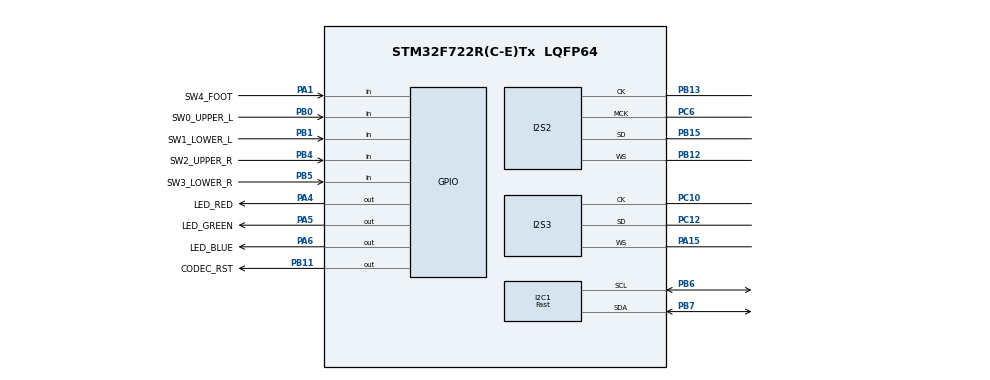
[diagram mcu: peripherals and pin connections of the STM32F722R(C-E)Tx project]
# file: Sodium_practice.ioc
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Mcu.Family=STM32F7
Dma.SPI2_TX.0.MemInc=DMA_MINC_ENABLE
PH0-OSC_IN.Signal=RCC_OSC_IN
RCC.CortexFreq_Value=216000000
I2C1.I2C_Speed_Mode=I2C_Fast
PC12.Signal=I2S3_SD
PC10.Signal=I2S3_CK
CORTEX_M7.PREFETCH_ENABLE=1
PA6.GPIO_Label=LED_BLUE
PB0.GPIO_Label=SW0_UPPER_L
PB11.Signal=GPIO_Output
NVIC.DMA1_Stream4_IRQn=true\:5\:0\:false\:false\:true\:true\:false\:true
PB13.Signal=I2S2_CK
PB15.Signal=I2S2_SD
Dma.SPI2_TX.0.Instance=DMA1_Stream4
RCC.SYSCLKSource=RCC_SYSCLKSOURCE_PLLCLK
ProjectManager.StackSize=0x4000
Dma.SPI2_TX.0.MemDataAlignment=DMA_MDATAALIGN_HALFWORD
FREERTOS.configENABLE_FPU=1
PB1.GPIO_PuPd=GPIO_PULLUP
RCC.HCLKFreq_Value=216000000
I2S3.Mode=I2S_MODE_SLAVE_RX
RCC.APB2TimFreq_Value=216000000
PB6.Signal=I2C1_SCL
PB6.Mode=I2C
Dma.SPI2_TX.0.Mode=DMA_CIRCULAR
PA1.GPIO_PuPd=GPIO_PULLUP
RCC.AHBFreq_Value=216000000
PH0-OSC_IN.Mode=HSE-External-Oscillator
RCC.HSE_VALUE=8000000
PA15.Mode=Half_Duplex_Slave
I2S3.ErrorAudioFreq=0.24 %
PA14.Mode=Serial_Wire
PB1.GPIO_Label=SW1_LOWER_L
PB7.Signal=I2C1_SDA
I2S2.DataFormat=I2S_DATAFORMAT_32B
VP_FREERTOS_VS_CMSIS_V1.Mode=CMSIS_V1
PH1-OSC_OUT.Mode=HSE-External-Oscillator
Mcu.Package=LQFP64
PB1.Signal=GPIO_Input
PA6.Signal=GPIO_Output
PB12.Mode=Half_Duplex_Master
NVIC.TimeBase=TIM7_IRQn
Dma.SPI3_RX.1.MemInc=DMA_MINC_ENABLE
NVIC.TimeBaseIP=TIM7
PA15.Signal=I2S3_WS
Dma.SPI2_TX.0.PeriphInc=DMA_PINC_DISABLE
RCC.APB2CLKDivider=RCC_HCLK_DIV2
PB5.GPIO_Label=SW3_LOWER_R
Dma.Request1=SPI3_RX
RCC.APB1TimFreq_Value=108000000
NVIC.DMA1_Stream0_IRQn=true\:5\:0\:false\:false\:true\:true\:false\:true
PB13.Mode=Half_Duplex_Master
Dma.Request0=SPI2_TX
PA4.GPIO_Label=LED_RED
NVIC.TIM7_IRQn=true\:0\:0\:false\:false\:true\:false\:false\:true
PB4.Signal=GPIO_Input
RCC.PLLSourceVirtual=RCC_PLLSOURCE_HSE
Dma.SPI3_RX.1.PeriphDataAlignment=DMA_PDATAALIGN_HALFWORD
I2S2.AudioFreq=I2S_AUDIOFREQ_44K
I2S3.FullDuplexMode=I2S_FULLDUPLEXMODE_DISABLE
CORTEX_M7.CPU_ICache=Enabled
FREERTOS.Tasks01=startTask,0,1024,StartDefaultTask,Default,NULL,Dynamic,NULL,NULL
I2S2.Instance=SPI$Index
VP_SYS_VS_tim7.Mode=TIM7
RCC.I2C1CLockSelection=RCC_I2C1CLKSOURCE_SYSCLK
PC10.Mode=Half_Duplex_Slave
PC6.Signal=I2S2_MCK
PB11.GPIO_Label=CODEC_RST
Dma.SPI3_RX.1.FIFOMode=DMA_FIFOMODE_DISABLE
Dma.SPI3_RX.1.PeriphInc=DMA_PINC_DISABLE
RCC.APB1CLKDivider=RCC_HCLK_DIV4
Dma.SPI3_RX.1.Priority=DMA_PRIORITY_VERY_HIGH
I2S3.DataFormat=I2S_DATAFORMAT_32B
Dma.SPI3_RX.1.Instance=DMA1_Stream0
Dma.SPI3_RX.1.MemDataAlignment=DMA_MDATAALIGN_HALFWORD
PA13.Signal=SYS_JTMS-SWDIO
ProjectManager.TargetToolchain=STM32CubeIDE
CORTEX_M7.ART_ACCLERATOR_ENABLE=1
PC6.Mode=Master_Clock_Activated
I2S2.VirtualMode=I2S_MODE_MASTER
I2C1.Timing=0x10A03AC5
I2S3.VirtualMode=I2S_MODE_SLAVE
PB4.GPIO_PuPd=GPIO_PULLUP
RCC.USBFreq_Value=216000000
RCC.LSE_VALUE=32768
PA1.Signal=GPIO_Input
PA5.Signal=GPIO_Output
I2S3.AudioFreq=I2S_AUDIOFREQ_44K
PC12.Mode=Half_Duplex_Slave
board=custom
RCC.VCOOutputFreq_Value=432000000
PB15.Mode=Half_Duplex_Master
RCC.APB2Freq_Value=108000000
PB4.GPIO_Label=SW2_UPPER_R
Dma.SPI2_TX.0.PeriphDataAlignment=DMA_PDATAALIGN_HALFWORD
PA1.GPIO_Label=SW4_FOOT
PH1-OSC_OUT.Signal=RCC_OSC_OUT
PA13.Mode=Serial_Wire
Mcu.Name=STM32F722R(C-E)Tx
Dma.SPI2_TX.0.FIFOMode=DMA_FIFOMODE_DISABLE
I2S2.FullDuplexMode=I2S_FULLDUPLEXMODE_DISABLE
PA4.Signal=GPIO_Output
Dma.SPI2_TX.0.Priority=DMA_PRIORITY_VERY_HIGH
RCC.SYSCLKFreq_VALUE=216000000
PB5.Signal=GPIO_Input
PA5.GPIO_Label=LED_GREEN
I2S2.ErrorAudioFreq=0.24 %
PB5.GPIO_PuPd=GPIO_PULLUP
PB7.Mode=I2C
Dma.SPI3_RX.1.Direction=DMA_PERIPH_TO_MEMORY
PA14.Signal=SYS_JTCK-SWCLK
ProjectManager.HeapSize=0x2000
Dma.SPI3_RX.1.Mode=DMA_CIRCULAR
RCC.HSI_VALUE=16000000
NVIC.PriorityGroup=NVIC_PRIORITYGROUP_4
I2S3.RealAudioFreq=44.108 KHz
RCC.PLLM=8
RCC.PLLN=432
CORTEX_M7.CPU_DCache=Enabled
I2S3.Instance=SPI$Index
Dma.SPI2_TX.0.Direction=DMA_MEMORY_TO_PERIPH
RCC.APB1Freq_Value=54000000
RCC.PLLI2SR=3
PB0.Signal=GPIO_Input
I2S2.RealAudioFreq=44.108 KHz
RCC.PLLI2SN=271
PB12.Signal=I2S2_WS
PB0.GPIO_PuPd=GPIO_PULLUP

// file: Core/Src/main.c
/* USER CODE BEGIN Header */
/**
 ******************************************************************************
 * @file           : main.c
 * @brief          : Main program body
 ******************************************************************************
 * @attention
 *
 * <h2><center>&copy; Copyright (c) 2021 STMicroelectronics.
 * All rights reserved.</center></h2>
 *
 * This software component is licensed by ST under Ultimate Liberty license
 * SLA0044, the "License"; You may not use this file except in compliance with
 * the License. You may obtain a copy of the License at:
 *                             www.st.com/SLA0044
 *
 ******************************************************************************
 */
/* USER CODE END Header */
#include "main.h"
#include "cmsis_os.h"

I2S_HandleTypeDef hi2s2;
I2S_HandleTypeDef hi2s3;
DMA_HandleTypeDef hdma_spi2_tx;
DMA_HandleTypeDef hdma_spi3_rx;

osThreadId startTaskHandle;

void SystemClock_Config(void);
static void MX_GPIO_Init(void);
static void MX_DMA_Init(void);
static void MX_I2C1_Init(void);
static void MX_I2S2_Init(void);
static void MX_I2S3_Init(void);
void StartDefaultTask(void const * argument);

int main(void)
{

  /* Enable I-Cache---------------------------------------------------------*/
  SCB_EnableICache();

  /* Enable D-Cache---------------------------------------------------------*/
  SCB_EnableDCache();

  /* MCU Configuration--------------------------------------------------------*/

  /* Reset of all peripherals, Initializes the Flash interface and the Systick. */
  HAL_Init();

  /* Configure the system clock */
  SystemClock_Config();

  /* Initialize all configured peripherals */
  MX_GPIO_Init();
  MX_DMA_Init();
  MX_I2C1_Init();
  MX_I2S2_Init();
  MX_I2S3_Init();

  /* Create the thread(s) */
  /* definition and creation of startTask */
  osThreadDef(startTask, StartDefaultTask, osPriorityNormal, 0, 1024);
  startTaskHandle = osThreadCreate(osThread(startTask), NULL);

  /* Start scheduler */
  osKernelStart();

  /* We should never get here as control is now taken by the scheduler */
  /* Infinite loop */
    while (1) {

    }
}

void SystemClock_Config(void)
{
  LL_FLASH_SetLatency(LL_FLASH_LATENCY_7);
  while(LL_FLASH_GetLatency()!= LL_FLASH_LATENCY_7)
  {
  }
  LL_PWR_SetRegulVoltageScaling(LL_PWR_REGU_VOLTAGE_SCALE1);
  LL_PWR_EnableOverDriveMode();
  LL_RCC_HSE_Enable();

   /* Wait till HSE is ready */
  while(LL_RCC_HSE_IsReady() != 1)
  {

  }
  LL_RCC_PLL_ConfigDomain_SYS(LL_RCC_PLLSOURCE_HSE, LL_RCC_PLLM_DIV_8, 432, LL_RCC_PLLP_DIV_2);
  LL_RCC_PLLI2S_ConfigDomain_I2S(LL_RCC_PLLSOURCE_HSE, LL_RCC_PLLM_DIV_8, 271, LL_RCC_PLLI2SR_DIV_3);
  LL_RCC_PLL_Enable();

   /* Wait till PLL is ready */
  while(LL_RCC_PLL_IsReady() != 1)
  {

  }
  LL_RCC_PLLI2S_Enable();

   /* Wait till PLL is ready */
  while(LL_RCC_PLLI2S_IsReady() != 1)
  {

  }
  LL_RCC_SetAHBPrescaler(LL_RCC_SYSCLK_DIV_1);
  LL_RCC_SetAPB1Prescaler(LL_RCC_APB1_DIV_4);
  LL_RCC_SetAPB2Prescaler(LL_RCC_APB2_DIV_2);
  LL_RCC_SetSysClkSource(LL_RCC_SYS_CLKSOURCE_PLL);

   /* Wait till System clock is ready */
  while(LL_RCC_GetSysClkSource() != LL_RCC_SYS_CLKSOURCE_STATUS_PLL)
  {

  }
  LL_SetSystemCoreClock(216000000);

   /* Update the time base */
  if (HAL_InitTick (TICK_INT_PRIORITY) != HAL_OK)
  {
    Error_Handler();
  }
  LL_RCC_SetI2SClockSource(LL_RCC_I2S1_CLKSOURCE_PLLI2S);
  LL_RCC_SetI2CClockSource(LL_RCC_I2C1_CLKSOURCE_SYSCLK);
}

static void MX_I2C1_Init(void)
{

  LL_I2C_InitTypeDef I2C_InitStruct = {0};

  LL_GPIO_InitTypeDef GPIO_InitStruct = {0};

  LL_AHB1_GRP1_EnableClock(LL_AHB1_GRP1_PERIPH_GPIOB);
  /**I2C1 GPIO Configuration
  PB6   ------> I2C1_SCL
  PB7   ------> I2C1_SDA
  */
  GPIO_InitStruct.Pin = LL_GPIO_PIN_6;
  GPIO_InitStruct.Mode = LL_GPIO_MODE_ALTERNATE;
  GPIO_InitStruct.Speed = LL_GPIO_SPEED_FREQ_VERY_HIGH;
  GPIO_InitStruct.OutputType = LL_GPIO_OUTPUT_OPENDRAIN;
  GPIO_InitStruct.Pull = LL_GPIO_PULL_UP;
  GPIO_InitStruct.Alternate = LL_GPIO_AF_4;
  LL_GPIO_Init(GPIOB, &GPIO_InitStruct);

  GPIO_InitStruct.Pin = LL_GPIO_PIN_7;
  GPIO_InitStruct.Mode = LL_GPIO_MODE_ALTERNATE;
  GPIO_InitStruct.Speed = LL_GPIO_SPEED_FREQ_VERY_HIGH;
  GPIO_InitStruct.OutputType = LL_GPIO_OUTPUT_OPENDRAIN;
  GPIO_InitStruct.Pull = LL_GPIO_PULL_UP;
  GPIO_InitStruct.Alternate = LL_GPIO_AF_4;
  LL_GPIO_Init(GPIOB, &GPIO_InitStruct);

  /* Peripheral clock enable */
  LL_APB1_GRP1_EnableClock(LL_APB1_GRP1_PERIPH_I2C1);

  /** I2C Initialization
  */
  LL_I2C_EnableAutoEndMode(I2C1);
  LL_I2C_SetOwnAddress2(I2C1, 0, LL_I2C_OWNADDRESS2_NOMASK);
  LL_I2C_DisableOwnAddress2(I2C1);
  LL_I2C_DisableGeneralCall(I2C1);
  LL_I2C_EnableClockStretching(I2C1);
  I2C_InitStruct.PeripheralMode = LL_I2C_MODE_I2C;
  I2C_InitStruct.Timing = 0x10A03AC5;
  I2C_InitStruct.AnalogFilter = LL_I2C_ANALOGFILTER_ENABLE;
  I2C_InitStruct.DigitalFilter = 0;
  I2C_InitStruct.OwnAddress1 = 0;
  I2C_InitStruct.TypeAcknowledge = LL_I2C_ACK;
  I2C_InitStruct.OwnAddrSize = LL_I2C_OWNADDRESS1_7BIT;
  LL_I2C_Init(I2C1, &I2C_InitStruct);

}

static void MX_I2S2_Init(void)
{

  hi2s2.Instance = SPI2;
  hi2s2.Init.Mode = I2S_MODE_MASTER_TX;
  hi2s2.Init.Standard = I2S_STANDARD_PHILIPS;
  hi2s2.Init.DataFormat = I2S_DATAFORMAT_32B;
  hi2s2.Init.MCLKOutput = I2S_MCLKOUTPUT_ENABLE;
  hi2s2.Init.AudioFreq = I2S_AUDIOFREQ_44K;
  hi2s2.Init.CPOL = I2S_CPOL_LOW;
  hi2s2.Init.ClockSource = I2S_CLOCK_PLL;
  if (HAL_I2S_Init(&hi2s2) != HAL_OK)
  {
    Error_Handler();
  }

}

static void MX_I2S3_Init(void)
{

  hi2s3.Instance = SPI3;
  hi2s3.Init.Mode = I2S_MODE_SLAVE_RX;
  hi2s3.Init.Standard = I2S_STANDARD_PHILIPS;
  hi2s3.Init.DataFormat = I2S_DATAFORMAT_32B;
  hi2s3.Init.MCLKOutput = I2S_MCLKOUTPUT_DISABLE;
  hi2s3.Init.AudioFreq = I2S_AUDIOFREQ_44K;
  hi2s3.Init.CPOL = I2S_CPOL_LOW;
  hi2s3.Init.ClockSource = I2S_CLOCK_PLL;
  if (HAL_I2S_Init(&hi2s3) != HAL_OK)
  {
    Error_Handler();
  }

}

static void MX_DMA_Init(void)
{

  /* Init with LL driver */
  /* DMA controller clock enable */
  LL_AHB1_GRP1_EnableClock(LL_AHB1_GRP1_PERIPH_DMA1);

  /* DMA interrupt init */
  /* DMA1_Stream0_IRQn interrupt configuration */
  HAL_NVIC_SetPriority(DMA1_Stream0_IRQn, 5, 0);
  HAL_NVIC_EnableIRQ(DMA1_Stream0_IRQn);
  /* DMA1_Stream4_IRQn interrupt configuration */
  HAL_NVIC_SetPriority(DMA1_Stream4_IRQn, 5, 0);
  HAL_NVIC_EnableIRQ(DMA1_Stream4_IRQn);

}

static void MX_GPIO_Init(void)
{
  LL_GPIO_InitTypeDef GPIO_InitStruct = {0};

  /* GPIO Ports Clock Enable */
  LL_AHB1_GRP1_EnableClock(LL_AHB1_GRP1_PERIPH_GPIOH);
  LL_AHB1_GRP1_EnableClock(LL_AHB1_GRP1_PERIPH_GPIOA);
  LL_AHB1_GRP1_EnableClock(LL_AHB1_GRP1_PERIPH_GPIOB);
  LL_AHB1_GRP1_EnableClock(LL_AHB1_GRP1_PERIPH_GPIOC);

  /**/
  LL_GPIO_ResetOutputPin(LED_RED_GPIO_Port, LED_RED_Pin);

  /**/
  LL_GPIO_ResetOutputPin(LED_GREEN_GPIO_Port, LED_GREEN_Pin);

  /**/
  LL_GPIO_ResetOutputPin(LED_BLUE_GPIO_Port, LED_BLUE_Pin);

  /**/
  LL_GPIO_ResetOutputPin(CODEC_RST_GPIO_Port, CODEC_RST_Pin);

  /**/
  GPIO_InitStruct.Pin = SW4_FOOT_Pin;
  GPIO_InitStruct.Mode = LL_GPIO_MODE_INPUT;
  GPIO_InitStruct.Pull = LL_GPIO_PULL_UP;
  LL_GPIO_Init(SW4_FOOT_GPIO_Port, &GPIO_InitStruct);

  /**/
  GPIO_InitStruct.Pin = LED_RED_Pin;
  GPIO_InitStruct.Mode = LL_GPIO_MODE_OUTPUT;
  GPIO_InitStruct.Speed = LL_GPIO_SPEED_FREQ_LOW;
  GPIO_InitStruct.OutputType = LL_GPIO_OUTPUT_PUSHPULL;
  GPIO_InitStruct.Pull = LL_GPIO_PULL_NO;
  LL_GPIO_Init(LED_RED_GPIO_Port, &GPIO_InitStruct);

  /**/
  GPIO_InitStruct.Pin = LED_GREEN_Pin;
  GPIO_InitStruct.Mode = LL_GPIO_MODE_OUTPUT;
  GPIO_InitStruct.Speed = LL_GPIO_SPEED_FREQ_LOW;
  GPIO_InitStruct.OutputType = LL_GPIO_OUTPUT_PUSHPULL;
  GPIO_InitStruct.Pull = LL_GPIO_PULL_NO;
  LL_GPIO_Init(LED_GREEN_GPIO_Port, &GPIO_InitStruct);

  /**/
  GPIO_InitStruct.Pin = LED_BLUE_Pin;
  GPIO_InitStruct.Mode = LL_GPIO_MODE_OUTPUT;
  GPIO_InitStruct.Speed = LL_GPIO_SPEED_FREQ_LOW;
  GPIO_InitStruct.OutputType = LL_GPIO_OUTPUT_PUSHPULL;
  GPIO_InitStruct.Pull = LL_GPIO_PULL_NO;
  LL_GPIO_Init(LED_BLUE_GPIO_Port, &GPIO_InitStruct);

  /**/
  GPIO_InitStruct.Pin = SW0_UPPER_L_Pin;
  GPIO_InitStruct.Mode = LL_GPIO_MODE_INPUT;
  GPIO_InitStruct.Pull = LL_GPIO_PULL_UP;
  LL_GPIO_Init(SW0_UPPER_L_GPIO_Port, &GPIO_InitStruct);

  /**/
  GPIO_InitStruct.Pin = SW1_LOWER_L_Pin;
  GPIO_InitStruct.Mode = LL_GPIO_MODE_INPUT;
  GPIO_InitStruct.Pull = LL_GPIO_PULL_UP;
  LL_GPIO_Init(SW1_LOWER_L_GPIO_Port, &GPIO_InitStruct);

  /**/
  GPIO_InitStruct.Pin = CODEC_RST_Pin;
  GPIO_InitStruct.Mode = LL_GPIO_MODE_OUTPUT;
  GPIO_InitStruct.Speed = LL_GPIO_SPEED_FREQ_LOW;
  GPIO_InitStruct.OutputType = LL_GPIO_OUTPUT_PUSHPULL;
  GPIO_InitStruct.Pull = LL_GPIO_PULL_NO;
  LL_GPIO_Init(CODEC_RST_GPIO_Port, &GPIO_InitStruct);

  /**/
  GPIO_InitStruct.Pin = SW2_UPPER_R_Pin;
  GPIO_InitStruct.Mode = LL_GPIO_MODE_INPUT;
  GPIO_InitStruct.Pull = LL_GPIO_PULL_UP;
  LL_GPIO_Init(SW2_UPPER_R_GPIO_Port, &GPIO_InitStruct);

  /**/
  GPIO_InitStruct.Pin = SW3_LOWER_R_Pin;
  GPIO_InitStruct.Mode = LL_GPIO_MODE_INPUT;
  GPIO_InitStruct.Pull = LL_GPIO_PULL_UP;
  LL_GPIO_Init(SW3_LOWER_R_GPIO_Port, &GPIO_InitStruct);

}

void StartDefaultTask(void const * argument)
{
  /* USER CODE BEGIN 5 */
    /* Infinite loop */
    for (;;) {
        osDelay(500);
        LL_GPIO_TogglePin(LED_RED_GPIO_Port, LED_RED_Pin);
        LL_GPIO_TogglePin(LED_GREEN_GPIO_Port, LED_GREEN_Pin);
        LL_GPIO_TogglePin(LED_BLUE_GPIO_Port, LED_BLUE_Pin);
    }
  /* USER CODE END 5 */
}

 /**
  * @brief  Period elapsed callback in non blocking mode
  * @note   This function is called  when TIM7 interrupt took place, inside
  * HAL_TIM_IRQHandler(). It makes a direct call to HAL_IncTick() to increment
  * a global variable "uwTick" used as application time base.
  * @param  htim : TIM handle
  * @retval None
  */
void HAL_TIM_PeriodElapsedCallback(TIM_HandleTypeDef *htim)
{
  if (htim->Instance == TIM7) {
    HAL_IncTick();
  }
}

void Error_Handler(void)
{
    __disable_irq();
    while (1) {}
}

/************************ (C) COPYRIGHT STMicroelectronics *****END OF FILE****/

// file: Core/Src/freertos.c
/* USER CODE BEGIN Header */
/**
 ******************************************************************************
 * File Name          : freertos.c
 * Description        : Code for freertos applications
 ******************************************************************************
 * @attention
 *
 * <h2><center>&copy; Copyright (c) 2021 STMicroelectronics.
 * All rights reserved.</center></h2>
 *
 * This software component is licensed by ST under Ultimate Liberty license
 * SLA0044, the "License"; You may not use this file except in compliance with
 * the License. You may obtain a copy of the License at:
 *                             www.st.com/SLA0044
 *
 ******************************************************************************
 */
/* USER CODE END Header */

#include "FreeRTOS.h"
#include "task.h"
#include "main.h"

/* GetIdleTaskMemory prototype (linked to static allocation support) */
void vApplicationGetIdleTaskMemory( StaticTask_t **ppxIdleTaskTCBBuffer, StackType_t **ppxIdleTaskStackBuffer, uint32_t *pulIdleTaskStackSize );

/* USER CODE BEGIN GET_IDLE_TASK_MEMORY */
static StaticTask_t xIdleTaskTCBBuffer;
static StackType_t xIdleStack[configMINIMAL_STACK_SIZE];

void vApplicationGetIdleTaskMemory(
    StaticTask_t** ppxIdleTaskTCBBuffer, StackType_t** ppxIdleTaskStackBuffer, uint32_t* pulIdleTaskStackSize) {
    *ppxIdleTaskTCBBuffer = &xIdleTaskTCBBuffer;
    *ppxIdleTaskStackBuffer = &xIdleStack[0];
    *pulIdleTaskStackSize = configMINIMAL_STACK_SIZE;
    /* place for user code */
}
/* USER CODE END GET_IDLE_TASK_MEMORY */

/************************ (C) COPYRIGHT STMicroelectronics *****END OF FILE****/
